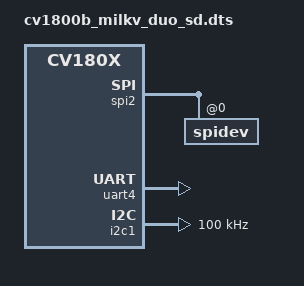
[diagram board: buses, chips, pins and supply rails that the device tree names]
/dts-v1/;
#include "cv180x_base_riscv.dtsi"
#include "cv180x_asic_qfn.dtsi"
#include "cv180x_asic_sd.dtsi"
#include "cv180x_default_memmap.dtsi"

&mipi_rx{
	snsr-reset = <&portc 8 GPIO_ACTIVE_LOW>, <&portc 8 GPIO_ACTIVE_LOW>, <&portc 8 GPIO_ACTIVE_LOW>;
};

&spi2 {
	status = "okay";

	spidev@0 {
		status = "okay";
	};
};

&uart4 {
	status = "okay";
};

&i2c1 {
       status = "okay";
       clock-frequency = <100000>;
};

/ {
		mailbox: mailbox@0x1900000 {
		#mbox-cells = <1>;
		compatible = "cvitek,cv180x-mailbox";
		reg = <0x0 0x01900000 0x0 0x1000>;
		// reg-names = "mailbox";
		interrupts = <101 IRQ_TYPE_LEVEL_HIGH>;
		interrupt-names = "mailbox";
		interrupt-parent = <&plic0>;
	};

	mailbox-test {
		compatible = "mailbox-test";
		mbox-names = "rx", "tx";
		mboxes = <&mailbox 0 &mailbox 1>;
	};
};

